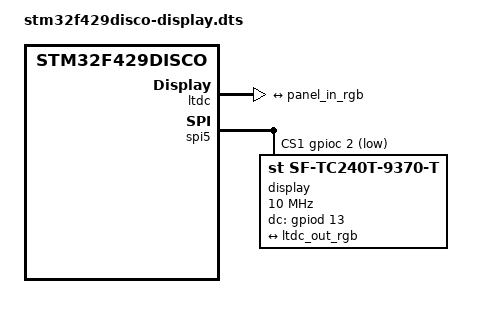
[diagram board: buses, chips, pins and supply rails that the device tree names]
/*
 * Display variant built only when BR2_PACKAGE_DISPLAYEXAMPLE is selected.
 * The base board DTS remains display-free for minimal firmware builds.
 */
#include "stm32f429disco-custom.dts"

&ltdc {
	status = "okay";
	pinctrl-0 = <&ltdc_pins_b>;
	pinctrl-names = "default";

	port {
		ltdc_out_rgb: endpoint {
			remote-endpoint = <&panel_in_rgb>;
		};
	};
};

&spi5 {
	/* CS0 is the gyroscope; CS1 is the LCD controller. */
	cs-gpios = <&gpioc 1 GPIO_ACTIVE_LOW>,
		     <&gpioc 2 GPIO_ACTIVE_LOW>;

	display: display@1 {
		compatible = "st,sf-tc240t-9370-t", "ilitek,ili9341";
		reg = <1>;
		spi-3wire;
		spi-max-frequency = <10000000>;
		dc-gpios = <&gpiod 13 GPIO_ACTIVE_HIGH>;

		port {
			panel_in_rgb: endpoint {
				remote-endpoint = <&ltdc_out_rgb>;
			};
		};
	};
};
